# N32MC47x_DP47x register map
Vendor: Nsingtech Ltd.; File version: 1.0
Registers are 32-bit, read-write, reset 0x0 unless marked. A register's access mark holds for its fields unless they carry their own. Offsets are from the block's base; [hi:lo] are bit positions; {n}, {i} and the like mark numbered series.

## GTIM8 — General purpose timer 8
Base 0x40010C00
Same registers: GTIM9 0x40011000, GTIM10 0x40011400
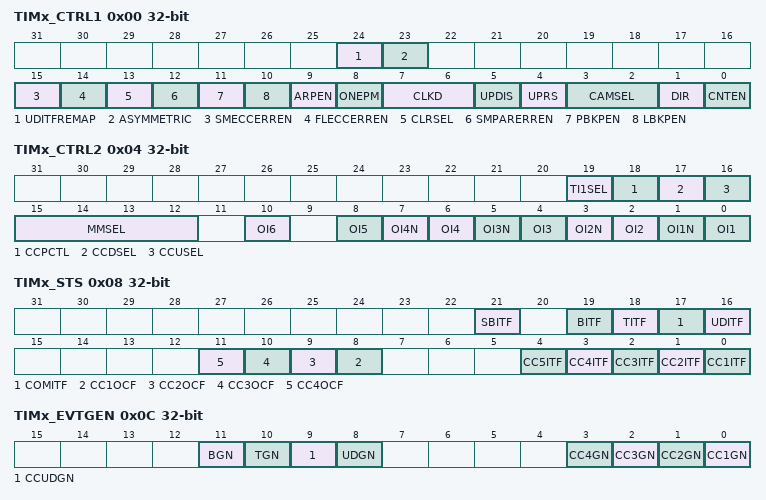
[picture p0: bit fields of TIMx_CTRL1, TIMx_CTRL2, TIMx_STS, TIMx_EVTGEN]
0x00 TIMx_CTRL1
  [24] UDITFREMAP, [23] ASYMMETRIC, [15] SMECCERREN, [14] FLECCERREN, [13] CLRSEL, [12] SMPARERREN, [11] PBKPEN, [10] LBKPEN, [9] ARPEN, [8] ONEPM, [7:6] CLKD, [5] UPDIS, [4] UPRS, [3:2] CAMSEL, [1] DIR, [0] CNTEN
0x04 TIMx_CTRL2
  [19] TI1SEL, [18] CCPCTL, [17] CCDSEL, [16] CCUSEL, [15:12] MMSEL, [2n-2] OI{n} (n=1..6), [2n-1] OI{n}N (n=1..4)
0x08 TIMx_STS
  [21] SBITF, [19] BITF, [18] TITF, [17] COMITF, [16] UDITF, [n+7] CC{n}OCF (n=1..4), [n-1] CC{n}ITF (n=1..5)
0x0C TIMx_EVTGEN
  [11] BGN, [10] TGN, [9] CCUDGN, [8] UDGN, [n-1] CC{n}GN (n=1..4)
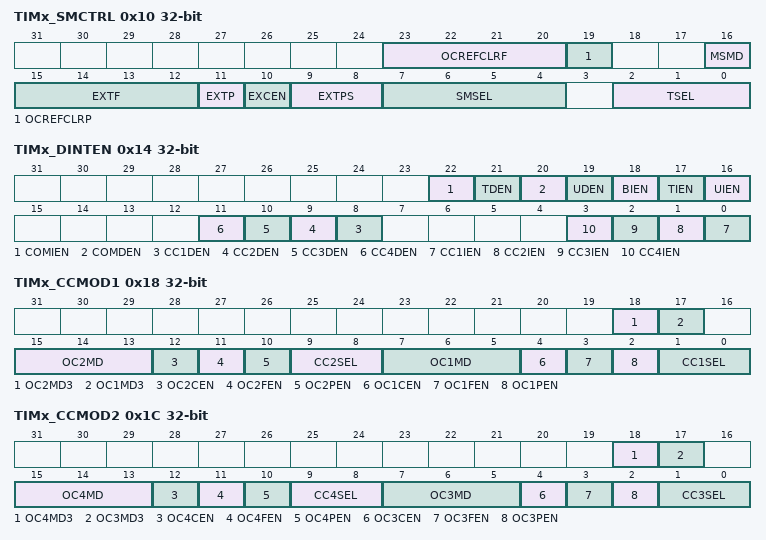
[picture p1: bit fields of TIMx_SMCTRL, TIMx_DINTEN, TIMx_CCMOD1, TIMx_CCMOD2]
0x10 TIMx_SMCTRL
  [23:20] OCREFCLRF, [19] OCREFCLRP, [16] MSMD, [15:12] EXTF, [11] EXTP, [10] EXCEN, [9:8] EXTPS, [7:4] SMSEL, [2:0] TSEL
0x14 TIMx_DINTEN
  [22] COMIEN, [21] TDEN, [20] COMDEN, [19] UDEN, [18] BIEN, [17] TIEN, [16] UIEN, [n+7] CC{n}DEN (n=1..4), [n-1] CC{n}IEN (n=1..4)
0x18 TIMx_CCMOD1
  [18] OC2MD3, [17] OC1MD3, [15:13] OC2MD, [12] OC2CEN, [11] OC2FEN, [10] OC2PEN, [9:8] CC2SEL, [7:5] OC1MD, [4] OC1CEN, [3] OC1FEN, [2] OC1PEN, [1:0] CC1SEL
0x1C TIMx_CCMOD2
  [18] OC4MD3, [17] OC3MD3, [15:13] OC4MD, [12] OC4CEN, [11] OC4FEN, [10] OC4PEN, [9:8] CC4SEL, [7:5] OC3MD, [4] OC3CEN, [3] OC3FEN, [2] OC3PEN, [1:0] CC3SEL
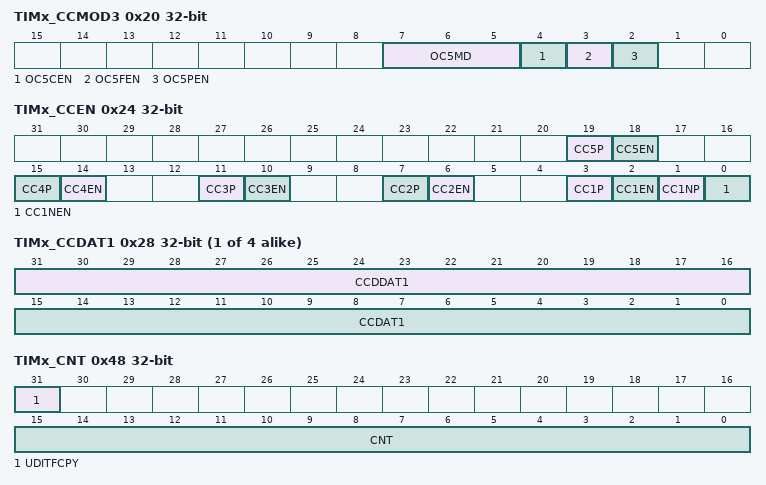
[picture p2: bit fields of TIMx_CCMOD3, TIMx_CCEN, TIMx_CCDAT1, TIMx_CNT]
0x20 TIMx_CCMOD3
  [7:5] OC5MD, [4] OC5CEN, [3] OC5FEN, [2] OC5PEN
0x24 TIMx_CCEN
  [4n-1] CC{n}P (n=1..5), [4n-2] CC{n}EN (n=1..5), [1] CC1NP, [0] CC1NEN
{0x24+4i} TIMx_CCDAT{i} (i=1..4)
  [31:16] CCDDAT{i}, [15:0] CCDAT{i}
0x38 TIMx_CCDAT5
  [15:0] CCDAT5
0x40 TIMx_PSC
  [15:0] PSC
0x44 TIMx_AR reset 0xFFFF
  [15:0] AR
0x48 TIMx_CNT
  [31] UDITFCPY, [15:0] CNT
0x4C TIMx_REPCNT
  [7:0] REPCNT
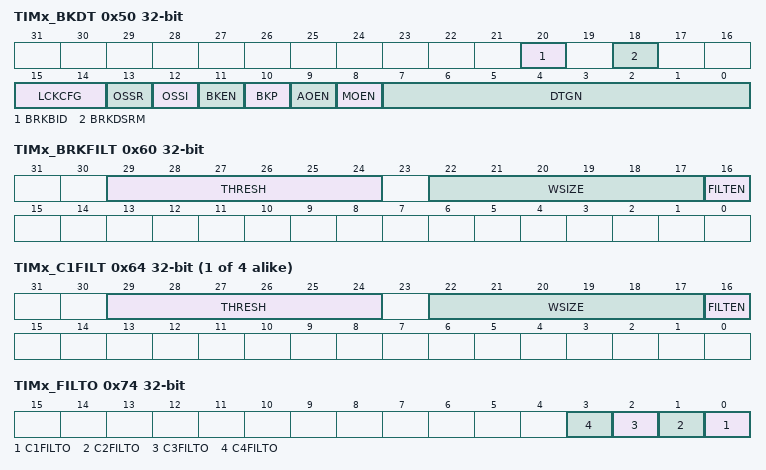
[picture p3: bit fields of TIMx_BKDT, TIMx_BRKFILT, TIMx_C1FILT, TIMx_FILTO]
0x50 TIMx_BKDT
  [20] BRKBID, [18] BRKDSRM, [15:14] LCKCFG, [13] OSSR, [12] OSSI, [11] BKEN, [10] BKP, [9] AOEN, [8] MOEN, [7:0] DTGN
0x60 TIMx_BRKFILT
  [29:24] THRESH, [22:17] WSIZE, [16] FILTEN
{0x60+4i} TIMx_C{i}FILT (i=1..4)
  [29:24] THRESH, [22:17] WSIZE, [16] FILTEN
0x74 TIMx_FILTO
  [n-1] C{n}FILTO (n=1..4)
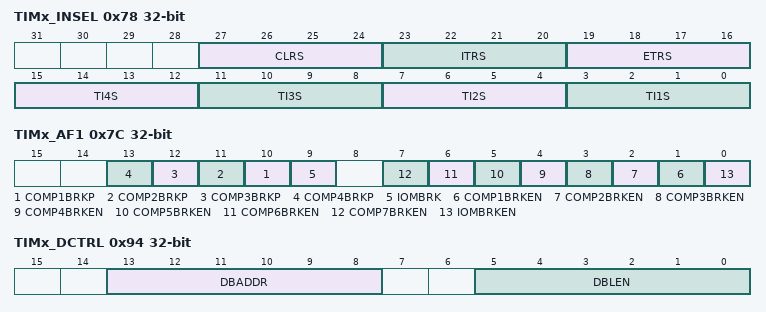
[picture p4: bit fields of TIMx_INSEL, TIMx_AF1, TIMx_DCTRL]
0x78 TIMx_INSEL
  [27:24] CLRS, [23:20] ITRS, [19:16] ETRS, [4n-1:4n-4] TI{n}S (n=1..4)
0x7C TIMx_AF1
  [n+9] COMP{n}BRKP (n=1..4), [9] IOMBRK, [n] COMP{n}BRKEN (n=1..7), [0] IOMBRKEN
0x88 TIMx_SLIDFPSC
  [15:0] SLIDFPSC
0x94 TIMx_DCTRL
  [13:8] DBADDR, [5:0] DBLEN
0x98 TIMx_DADDR
  [31:0] BURST

## BTIM1 — Basic timer
Base 0x40003C00
Same registers: BTIM2 0x40004000
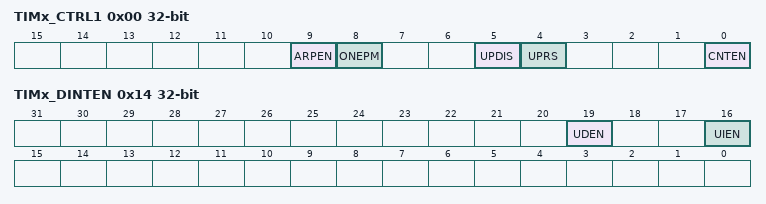
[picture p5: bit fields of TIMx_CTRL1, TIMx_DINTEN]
0x00 TIMx_CTRL1
  [9] ARPEN, [8] ONEPM, [5] UPDIS, [4] UPRS, [0] CNTEN
0x04 TIMx_CTRL2
  [15:12] MMSEL
0x08 TIMx_STS
  [16] UDITF
0x0C TIMx_EVTGEN
  [8] UDGN
0x14 TIMx_DINTEN
  [19] UDEN, [16] UIEN
0x40 TIMx_PSC
  [15:0] PSC
0x44 TIMx_AR reset 0xFFFFFFFF
0x48 TIMx_CNT

## I2C1 — Inter integrated circuit
Base 0x40001C00
Same registers: I2C2 0x40002000, I2C3 0x40007400, I2C4 0x40007800
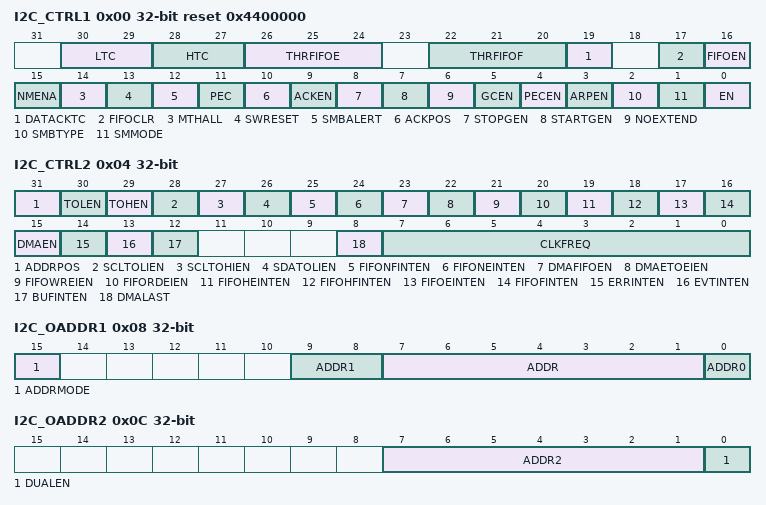
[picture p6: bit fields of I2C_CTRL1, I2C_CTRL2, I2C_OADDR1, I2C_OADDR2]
0x00 I2C_CTRL1 reset 0x4400000
  [30:29] LTC, [28:27] HTC, [26:24] THRFIFOE, [22:20] THRFIFOF, [19] DATACKTC, [17] FIFOCLR, [16] FIFOEN, [15] NMENA, [14] MTHALL, [13] SWRESET, [12] SMBALERT, [11] PEC, [10] ACKPOS, [9] ACKEN, [8] STOPGEN, [7] STARTGEN, [6] NOEXTEND, [5] GCEN, [4] PECEN, [3] ARPEN, [2] SMBTYPE, [1] SMMODE, [0] EN
0x04 I2C_CTRL2
  [31] ADDRPOS, [30] TOLEN, [29] TOHEN, [28] SCLTOLIEN, [27] SCLTOHIEN, [26] SDATOLIEN, [25] FIFONFINTEN, [24] FIFONEINTEN, [23] DMAFIFOEN, [22] DMAETOEIEN, [21] FIFOWREIEN, [20] FIFORDEIEN, [19] FIFOHEINTEN, [18] FIFOHFINTEN, [17] FIFOEINTEN, [16] FIFOFINTEN, [15] DMAEN, [14] ERRINTEN, [13] EVTINTEN, [12] BUFINTEN, [8] DMALAST, [7:0] CLKFREQ
0x08 I2C_OADDR1
  [15] ADDRMODE, [9:8] ADDR1, [7:1] ADDR, [0] ADDR0
0x0C I2C_OADDR2
  [7:1] ADDR2, [0] DUALEN
0x10 I2C_DAT
  [7:0] DATA
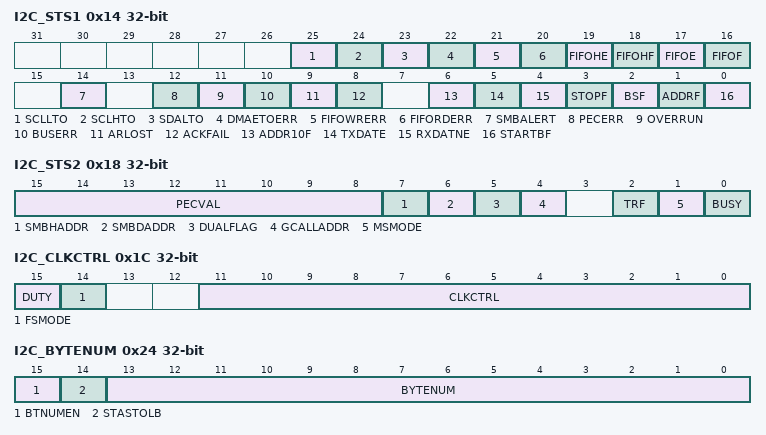
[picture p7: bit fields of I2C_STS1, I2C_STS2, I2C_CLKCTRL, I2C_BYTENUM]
0x14 I2C_STS1
  [25] SCLLTO, [24] SCLHTO, [23] SDALTO, [22] DMAETOERR, [21] FIFOWRERR, [20] FIFORDERR, [19] FIFOHE, [18] FIFOHF, [17] FIFOE, [16] FIFOF, [14] SMBALERT, [12] PECERR, [11] OVERRUN, [10] BUSERR, [9] ARLOST, [8] ACKFAIL, [6] ADDR10F, [5] TXDATE, [4] RXDATNE, [3] STOPF, [2] BSF, [1] ADDRF, [0] STARTBF
0x18 I2C_STS2
  [15:8] PECVAL, [7] SMBHADDR, [6] SMBDADDR, [5] DUALFLAG, [4] GCALLADDR, [2] TRF, [1] MSMODE, [0] BUSY
0x1C I2C_CLKCTRL
  [15] DUTY, [14] FSMODE, [11:0] CLKCTRL
0x20 I2C_TMRISE reset 0x2
  [7:0] TMRISE
0x24 I2C_BYTENUM
  [15] BTNUMEN, [14] STASTOLB, [13:0] BYTENUM
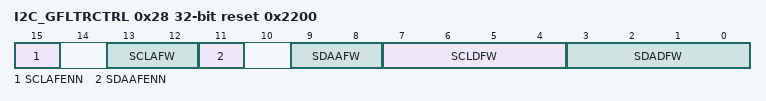
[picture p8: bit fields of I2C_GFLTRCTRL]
0x28 I2C_GFLTRCTRL reset 0x2200
  [15] SCLAFENN, [13:12] SCLAFW, [11] SDAAFENN, [9:8] SDAAFW, [7:4] SCLDFW, [3:0] SDADFW
0x2C I2C_FIFODAT
  [7:0] FIFODAT
